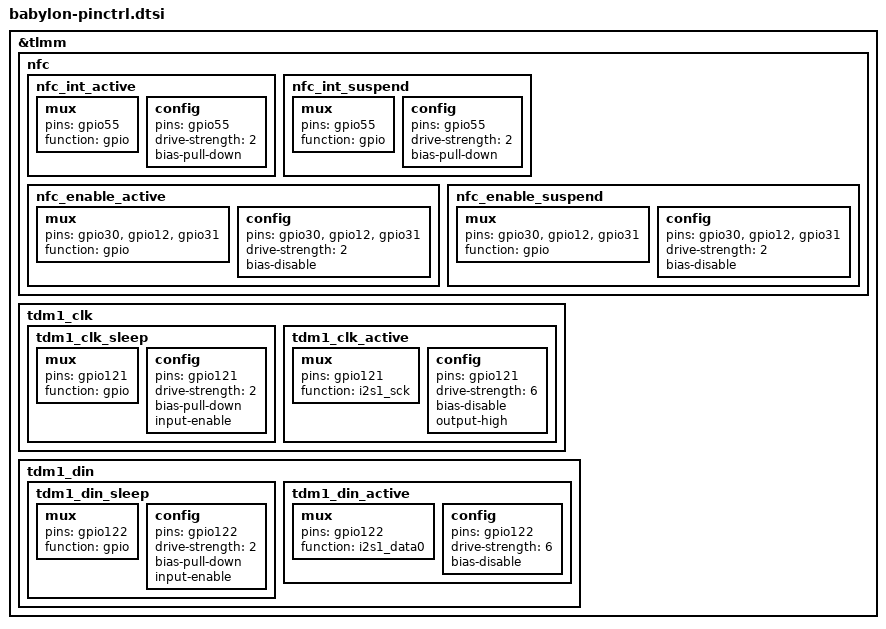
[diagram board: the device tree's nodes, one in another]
/*for babylon pinctrl */
&tlmm {
	nfc {
		nfc_int_active: nfc_int_active {
			/* active state */
			mux {
				/* NFC Read Interrupt */
				pins = "gpio55";
				function = "gpio";
			};

			config {
				pins = "gpio55";
				drive-strength = <2>; /* 2 MA */
				bias-pull-down;
			};
		};

		nfc_int_suspend: nfc_int_suspend {
			/* sleep state */
			mux {
				/* NFC Read Interrupt */
				pins = "gpio55";
				function = "gpio";
			};

			config {
				pins = "gpio55";
				drive-strength = <2>; /* 2 MA */
				bias-pull-down;
			};
		};

		nfc_enable_active: nfc_enable_active {
			mux {
				/* Enable, Firmware and Clock request gpios */
				pins = "gpio30", "gpio12", "gpio31";
				function = "gpio";
			};

			config {
				pins = "gpio30", "gpio12", "gpio31";
				drive-strength = <2>; /* 2 MA */
				bias-disable;
			};
		};

		nfc_enable_suspend: nfc_enable_suspend {
			mux {
				pins = "gpio30", "gpio12", "gpio31";
				function = "gpio";
			};

			config {
				pins = "gpio30", "gpio12", "gpio31";
				drive-strength = <2>; /* 2 MA */
				bias-disable;
			};
		};
	};

	tdm1_clk {
		tdm1_clk_sleep: tdm1_clk_sleep {
			mux {
				pins = "gpio121";
				function = "gpio";
			};

			config {
				pins = "gpio121";
				drive-strength = <2>;   /* 2 mA */
				bias-pull-down;         /* PULL DOWN */
				input-enable;
			};
		};

		tdm1_clk_active: tdm1_clk_active {
			mux {
				pins = "gpio121";
				function = "i2s1_sck";
			};

			config {
				pins = "gpio121";
				drive-strength = <6>;   /* 6 mA */
				bias-disable;           /* NO PULL */
				output-high;
			};
		};
	};

	tdm1_din {
		tdm1_din_sleep: tdm1_din_sleep {
			mux {
				pins = "gpio122";
				function = "gpio";
			};

			config {
				pins = "gpio122";
				drive-strength = <2>;   /* 2 mA */
				bias-pull-down;         /* PULL DOWN */
				input-enable;
			};
		};

		tdm1_din_active: tdm1_din_active {
			mux {
				pins = "gpio122";
				function = "i2s1_data0";
			};

			config {
				pins = "gpio122";
				drive-strength = <6>;   /* 6 mA */
				bias-disable;           /* NO PULL */
			};
		};
	};
};
